# TCM register map
Vendor: Texas Instruments
Peripheral module from a debugger description file (folder CC27xxx10).
Registers are 32-bit, access per field, reset 0x6F440010 unless marked. A register's access mark holds for its fields unless they carry their own. Offsets are as the file gives them; lines under a group give offsets from that group; [hi:lo] are bit positions; {n}, {i} and the like mark numbered series; 'fields as' and 'values as' point back to an identical list; <NAME> marks a mode.

## TCM — IO Controller
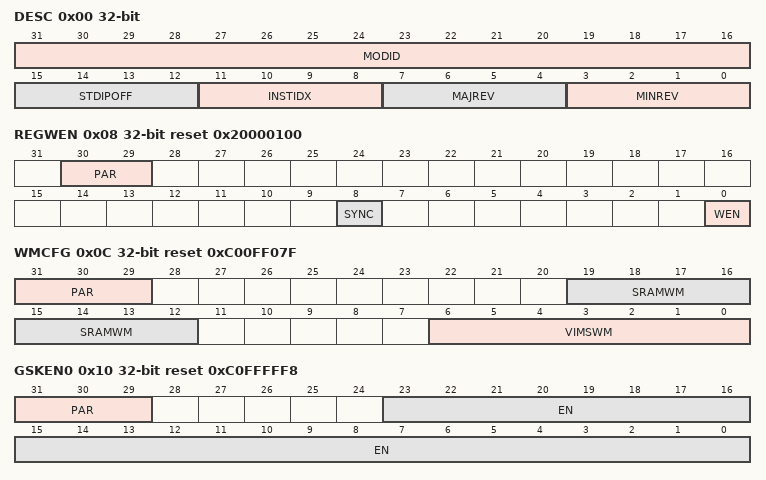
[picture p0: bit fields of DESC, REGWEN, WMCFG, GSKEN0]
0x00 DESC ro — This register identifies the peripheral and its exact version. This register is strictly read-only. Any write to this register will trigger chip reset.
  [31:16] MODID — Module identification contains a unique peripheral identification number.
  [15:12] STDIPOFF — Standard IP registers offset. Value 0 indicates Standard IP registers are not present. Any other value between 1 to 15 indicates standard IP registers start from address offset 64 * STDIPOFF from base address.
  [11:8] INSTIDX — Instance Index within the device. This will be a parameter to the RTL for modules that can have multiple instances.
  [7:4] MAJREV — Major rev of the IP
  [3:0] MINREV — Minor rev of the IP
0x04 DESCEX ro reset 0x29 — This register identifies the peripheral and its exact version. This register is strictly read-only. Any write to this register will trigger chip reset.
  [8:0] GSKCNT — Number of gaskets
0x08 REGWEN reset 0x20000100 — This register blocks writes to all the MMR of TCM once set. This register is protected by odd parity bit. It is sticky 1.
  [30:29] PAR rw — Parity bit. Bit 29 stores the odd parity for bits 0 to 7. Bit 30 stores the odd parity of bits 8 to 15. PAR[29] = ~WEN PAR[30] = ~SYNC
  [8] SYNC rw — Program this bit to 0 before writing to WMCFG or any of the gasket enable MMR i.e. GSKEN0, GSKEN1 etc. Once the MMR writes are done, program this bit to 1 again. Then WEN can be programmed 1 to lock the configuration. Note: Do not toggle SYNC and WEN in the same cycle
    1=RST (Reset); 0=SET
  [0] WEN rw — Write enable
    1=DIS (Disable writes); 0=EN (Enable writes)
0x0C WMCFG reset 0xC00FF07F — This register is used to configure SRAM and VIMS watermark. This register is protected by odd parity bits.
  [31:29] PAR rw — Parity bits. Bit 29 stores the odd parity for bits 0 to 7. Bit 30 stores the odd parity of bits 8 to 15. Bit 31 stores the odd parity of bits 23 to 16. PAR[29] = ~XOR(VIMSWM[7:0]) PAR[30] = ~XOR({[VIMSWM[9:8]], SRAMWM[15:12]}) PAR[31] = ~XOR(SRAMWM[21:16])
  [19:12] SRAMWM rw — SRAM Watermark. The address from (SRAM Base Address) to (SRAM Base Address + (SRAMWM + 1)$lt;$lt;10 - 1) is considered secure. The address from (SRAM Base Address + (SRAMWM + 1) $lt;$lt;10) to (SRAM Last Address) is considered Non-secure.
  [6:0] VIMSWM rw — VIMS Watermark The address from (Flash Main Base Address) to (Flash Main Base Address + (VIMSWM + 1)$lt;$lt;13 - 1) is considered secure. The address from (Flash Main Base Address + (VIMSWM + 1)$lt;$lt;13) to (Flash Main Last Address) is considered Non-secure.
0x10 GSKEN0 reset 0xC0FFFFF8 — This register is used to store gasket configuration. This register is protected by odd parity bits.
  [31:29] PAR rw — Parity bits. Bit 29 stores the odd parity for bits 0 to 7. Bit 30 stores the odd parity of bits 8 to 15. Bit 31 stores the odd parity of bits 23 to 16. PAR[29] = ~XOR(GSKEN0[7:0]) PAR[30] = ~XOR(GSKEN0[15:8]) PAR[31] = ~XOR(GSKEN0[23:16])
  [23:0] EN rw — Gasket enable. The gasket bit to IP mapping is given as follows :- [0] = DMA initiator gasket enable [1] = I2S initiator gasket enable [2] = HSM initiator gasket enable [3] = Radio target gasket enable [4] = AES target gasket enable [5] = I2S target gasket enable [6] = PDM target gasket enable [7] = AFA target gasket enable [8] = DMA target gasket enable [9] = CANFD target gasket enable [10] = APU target gasket enable [11] = APURAM target gasket enable [12] = GPIO target gasket enable [13] = SYSTIMER target gasket enable [14] = UART0 target gasket enable [15] = UART1 target gasket enable [16] = SPI0 target gasket enable [17] = SPI1 target gasket enable [18] = I2C0 target gasket enable [19] = EVTSVT target gasket enable [20] = ADC target gasket enable [21] = MICADC target gasket enable [22] = MICPGA target gasket enable [23] = CLKCTRL target gasket enable
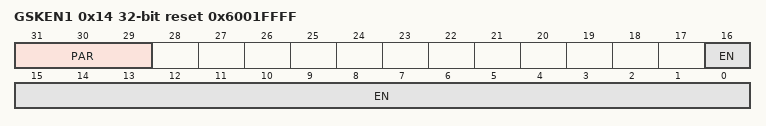
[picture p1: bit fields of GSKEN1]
0x14 GSKEN1 reset 0x6001FFFF — This register is used to store gasket configuration. This register is protected by odd parity bits.
  [31:29] PAR rw — Parity bits. Bit 29 stores the odd parity for bits 0 to 7. Bit 30 stores the odd parity of bits 8 to 15. Bit 31 stores the odd parity of bits 23 to 16. PAR[29] = ~XOR(GSKEN1[7:0]) PAR[30] = ~XOR(GSKEN1[15:8]) PAR[31] = ~XOR(GSKEN1[23:16])
  [16:0] EN rw — Gasket enable. The gasket bit to IP mapping is given as follows :- [0] = LGPT target gasket enable [1] = FLASH target gasket enable [2] = VIMS target gasket enable [3] = HSM target gasket enable [4] = PMC target gasket enable [5] = CKMDIG target gasket enable [6] = RTC target gasket enable [7] = IOC target gasket enable [8] = SYS0 target gasket enable [9] = EVTULL target gasket enable [10] = PMUDIG target gasket enable [11] = DEBUGSS target gasket enable [12] = HSM mailbox 1 target gasket enable [13] = HSM mailbox 2 target gasket enable [14] = HSM mailbox 3 target gasket enable [15] = HSM mailbox 4 target gasket enable [16] = HSM config target gasket enable
